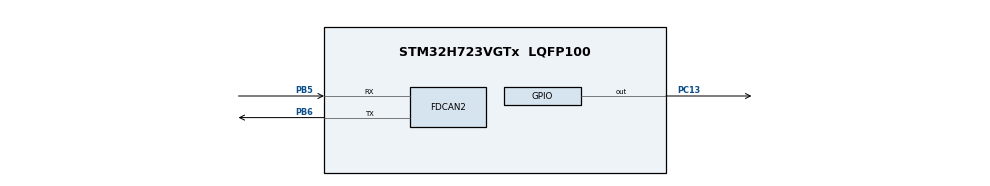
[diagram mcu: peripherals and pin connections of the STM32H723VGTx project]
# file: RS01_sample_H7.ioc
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CORTEX_M7.default_mode_Activation=1
FDCAN2.AutoRetransmission=ENABLE
FDCAN2.CalculateBaudRateNominal=1000000
FDCAN2.CalculateTimeBitNominal=1000
FDCAN2.CalculateTimeQuantumNominal=7.751937984496124
FDCAN2.DataTimeSeg1=6
FDCAN2.DataTimeSeg2=5
FDCAN2.ExtFiltersNbr=1
FDCAN2.NominalPrescaler=1
FDCAN2.NominalTimeSeg1=102
FDCAN2.NominalTimeSeg2=26
FDCAN2.RxFifo0ElmtsNbr=8
FDCAN2.StdFiltersNbr=1
FDCAN2.TxFifoQueueElmtsNbr=3
Mcu.Family=STM32H7
Mcu.Name=STM32H723VGTx
Mcu.Package=LQFP100
NVIC.FDCAN2_IT0_IRQn=true\:0\:0\:false\:false\:true\:true\:true\:true
NVIC.PriorityGroup=NVIC_PRIORITYGROUP_4
PA13(JTMS/SWDIO).Signal=DEBUG_JTMS-SWDIO
PA14(JTCK/SWCLK).Signal=DEBUG_JTCK-SWCLK
PB5.Mode=FDCAN_Activate
PB5.Signal=FDCAN2_RX
PB6.Mode=FDCAN_Activate
PB6.Signal=FDCAN2_TX
PC13.GPIO_ModeDefaultOutputPP=GPIO_MODE_OUTPUT_PP
PC13.PinState=GPIO_PIN_SET
PC13.Signal=GPIO_Output
ProjectManager.HeapSize=0x200
ProjectManager.StackSize=0x400
ProjectManager.TargetToolchain=MDK-ARM V5.32
RCC.ADCFreq_Value=129000000
RCC.APB1Freq_Value=64000000
RCC.APB2Freq_Value=64000000
RCC.APB3Freq_Value=64000000
RCC.APB4Freq_Value=64000000
RCC.CortexFreq_Value=64000000
RCC.HCLKFreq_Value=64000000
RCC.SYSCLKFreq_VALUE=64000000
RCC.USBFreq_Value=129000000
VP_MEMORYMAP_VS_MEMORYMAP.Mode=CurAppReg
board=custom

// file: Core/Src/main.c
/* USER CODE BEGIN Header */
/**
  ******************************************************************************
  * @file           : main.c
  * @brief          : Main program body
  ******************************************************************************
  * @attention
  *
  * Copyright (c) 2026 STMicroelectronics.
  * All rights reserved.
  *
  * This software is licensed under terms that can be found in the LICENSE file
  * in the root directory of this software component.
  * If no LICENSE file comes with this software, it is provided AS-IS.
  *
  ******************************************************************************
  */
/* USER CODE END Header */
#include "main.h"
#include "fdcan.h"
#include "gpio.h"

/* USER CODE BEGIN Includes */
#include "../../RS/Robstride.h"

/* USER CODE END Includes */

void SystemClock_Config(void);
static void MPU_Config(void);

int main(void)
{

  /* MPU Configuration--------------------------------------------------------*/
  MPU_Config();

  /* MCU Configuration--------------------------------------------------------*/

  /* Reset of all peripherals, Initializes the Flash interface and the Systick. */
  HAL_Init();

  /* Configure the system clock */
  SystemClock_Config();

  /* Initialize all configured peripherals */
  MX_GPIO_Init();
  MX_FDCAN2_Init();
  /* USER CODE BEGIN 2 */

  if (FDCAN2_ConfigureRxFilters() != HAL_OK) Error_Handler();
  if (HAL_FDCAN_Start(&hfdcan2) != HAL_OK) Error_Handler();
  /* Allow motor startup/configuration to finish before addressed queries. */
  HAL_Delay(3000U);

  /* USER CODE END 2 */

  /* Infinite loop */
  while (1)
  {

    /* USER CODE BEGIN 3 */
    RS01_PollFeedback();
    HAL_Delay(10U);
  }
  /* USER CODE END 3 */
}

void SystemClock_Config(void)
{
  RCC_OscInitTypeDef RCC_OscInitStruct = {0};
  RCC_ClkInitTypeDef RCC_ClkInitStruct = {0};

  /** Supply configuration update enable
  */
  HAL_PWREx_ConfigSupply(PWR_LDO_SUPPLY);

  /** Configure the main internal regulator output voltage
  */
  __HAL_PWR_VOLTAGESCALING_CONFIG(PWR_REGULATOR_VOLTAGE_SCALE3);

  while(!__HAL_PWR_GET_FLAG(PWR_FLAG_VOSRDY)) {}

  /** Initializes the RCC Oscillators according to the specified parameters
  * in the RCC_OscInitTypeDef structure.
  */
  RCC_OscInitStruct.OscillatorType = RCC_OSCILLATORTYPE_HSI;
  RCC_OscInitStruct.HSIState = RCC_HSI_DIV1;
  RCC_OscInitStruct.HSICalibrationValue = 64;
  RCC_OscInitStruct.PLL.PLLState = RCC_PLL_ON;
  RCC_OscInitStruct.PLL.PLLSource = RCC_PLLSOURCE_HSI;
  RCC_OscInitStruct.PLL.PLLM = 32;
  RCC_OscInitStruct.PLL.PLLN = 129;
  RCC_OscInitStruct.PLL.PLLP = 2;
  RCC_OscInitStruct.PLL.PLLQ = 2;
  RCC_OscInitStruct.PLL.PLLR = 2;
  RCC_OscInitStruct.PLL.PLLRGE = RCC_PLL1VCIRANGE_1;
  RCC_OscInitStruct.PLL.PLLVCOSEL = RCC_PLL1VCOWIDE;
  RCC_OscInitStruct.PLL.PLLFRACN = 0;
  if (HAL_RCC_OscConfig(&RCC_OscInitStruct) != HAL_OK)
  {
    Error_Handler();
  }

  /** Initializes the CPU, AHB and APB buses clocks
  */
  RCC_ClkInitStruct.ClockType = RCC_CLOCKTYPE_HCLK|RCC_CLOCKTYPE_SYSCLK
                              |RCC_CLOCKTYPE_PCLK1|RCC_CLOCKTYPE_PCLK2
                              |RCC_CLOCKTYPE_D3PCLK1|RCC_CLOCKTYPE_D1PCLK1;
  RCC_ClkInitStruct.SYSCLKSource = RCC_SYSCLKSOURCE_HSI;
  RCC_ClkInitStruct.SYSCLKDivider = RCC_SYSCLK_DIV1;
  RCC_ClkInitStruct.AHBCLKDivider = RCC_HCLK_DIV1;
  RCC_ClkInitStruct.APB3CLKDivider = RCC_APB3_DIV1;
  RCC_ClkInitStruct.APB1CLKDivider = RCC_APB1_DIV1;
  RCC_ClkInitStruct.APB2CLKDivider = RCC_APB2_DIV1;
  RCC_ClkInitStruct.APB4CLKDivider = RCC_APB4_DIV1;

  if (HAL_RCC_ClockConfig(&RCC_ClkInitStruct, FLASH_LATENCY_1) != HAL_OK)
  {
    Error_Handler();
  }
}

 /* MPU Configuration */

void MPU_Config(void)
{
  MPU_Region_InitTypeDef MPU_InitStruct = {0};

  /* Disables the MPU */
  HAL_MPU_Disable();

  /** Initializes and configures the Region and the memory to be protected
  */
  MPU_InitStruct.Enable = MPU_REGION_ENABLE;
  MPU_InitStruct.Number = MPU_REGION_NUMBER0;
  MPU_InitStruct.BaseAddress = 0x0;
  MPU_InitStruct.Size = MPU_REGION_SIZE_4GB;
  MPU_InitStruct.SubRegionDisable = 0x87;
  MPU_InitStruct.TypeExtField = MPU_TEX_LEVEL0;
  MPU_InitStruct.AccessPermission = MPU_REGION_NO_ACCESS;
  MPU_InitStruct.DisableExec = MPU_INSTRUCTION_ACCESS_DISABLE;
  MPU_InitStruct.IsShareable = MPU_ACCESS_SHAREABLE;
  MPU_InitStruct.IsCacheable = MPU_ACCESS_NOT_CACHEABLE;
  MPU_InitStruct.IsBufferable = MPU_ACCESS_NOT_BUFFERABLE;

  HAL_MPU_ConfigRegion(&MPU_InitStruct);
  /* Enables the MPU */
  HAL_MPU_Enable(MPU_PRIVILEGED_DEFAULT);

}

void Error_Handler(void)
{
  __disable_irq();
  while (1)
  {
  }
}
